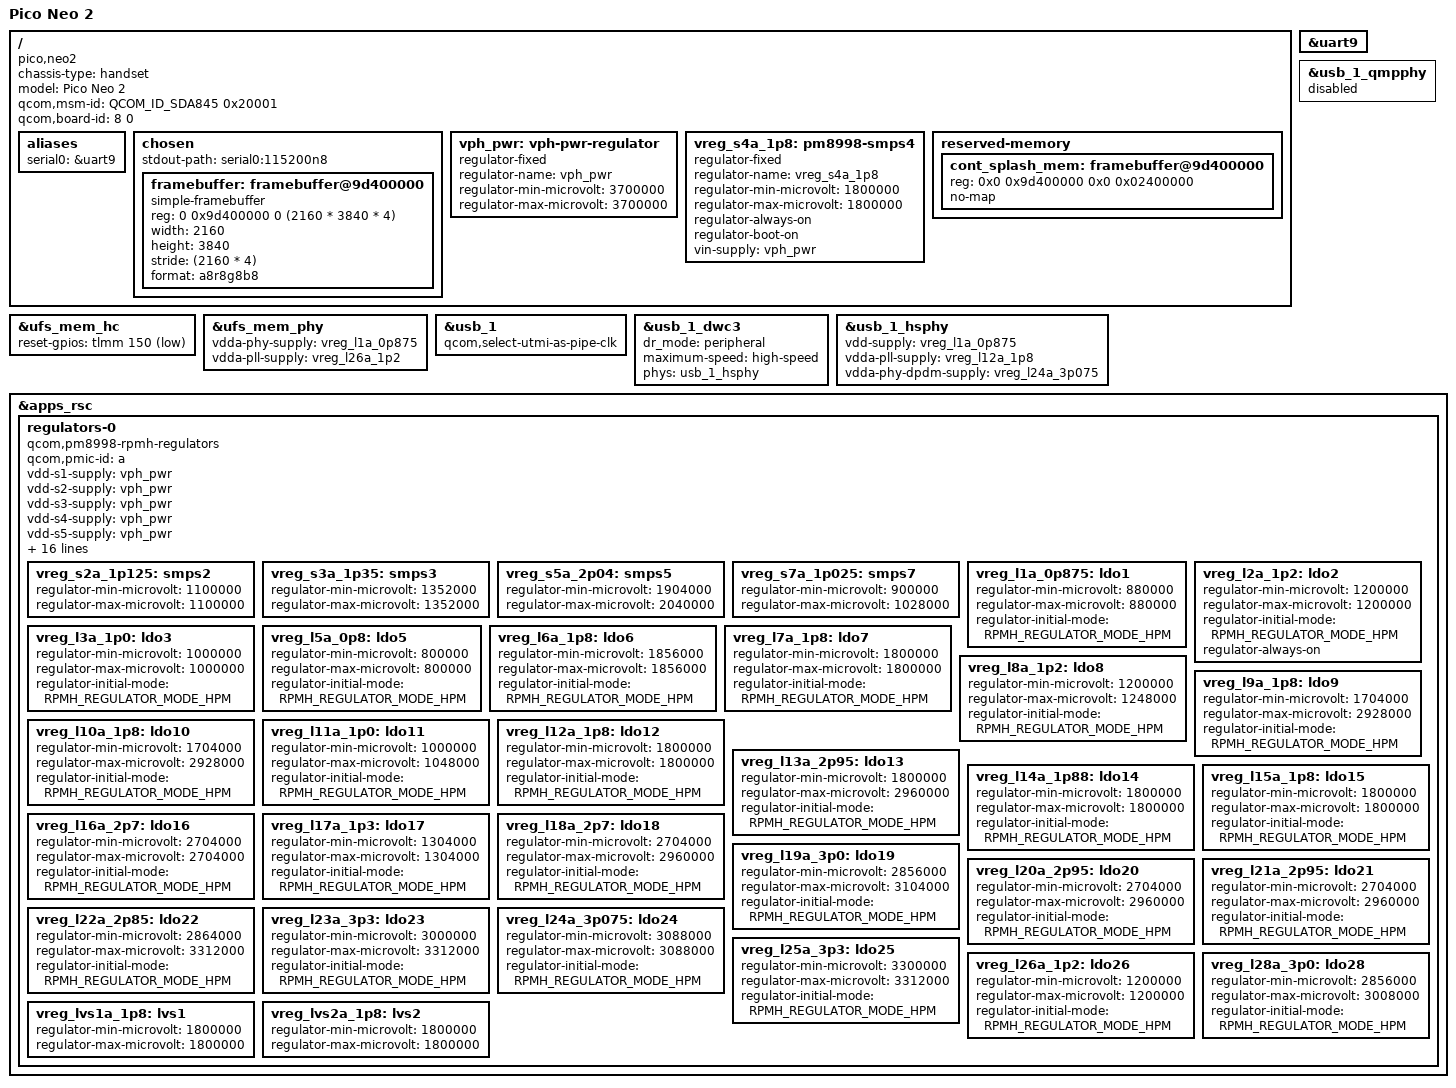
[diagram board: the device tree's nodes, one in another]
// SPDX-License-Identifier: GPL-2.0
/*
 * SDM845 Pico Neo 2 (A7B10) device tree source
 *
 * The Pico Neo 2 is a standalone VR headset based on the Qualcomm SDM845 SoC.
 * This DTS is maintained in the pico-linux repo and copied into the kernel
 * tree at build time.
 */

/dts-v1/;

#include <dt-bindings/arm/qcom,ids.h>
#include <dt-bindings/gpio/gpio.h>
#include <dt-bindings/regulator/qcom,rpmh-regulator.h>

#include "sdm845.dtsi"
#include "pm8998.dtsi"

/ {
	chassis-type = "handset";
	model = "Pico Neo 2";
	compatible = "pico,neo2", "qcom,sdm845";
	qcom,msm-id = <QCOM_ID_SDA845 0x20001>;
	qcom,board-id = <8 0>;

	aliases {
		serial0 = &uart9;
	};

	chosen {
		#address-cells = <2>;
		#size-cells = <2>;
		ranges;

		stdout-path = "serial0:115200n8";

		framebuffer: framebuffer@9d400000 {
			compatible = "simple-framebuffer";
			reg = <0 0x9d400000 0 (2160 * 3840 * 4)>;
			width = <2160>;
			height = <3840>;
			stride = <(2160 * 4)>;
			format = "a8r8g8b8";
		};
	};

	vph_pwr: vph-pwr-regulator {
		compatible = "regulator-fixed";
		regulator-name = "vph_pwr";
		regulator-min-microvolt = <3700000>;
		regulator-max-microvolt = <3700000>;
	};

	vreg_s4a_1p8: pm8998-smps4 {
		compatible = "regulator-fixed";
		regulator-name = "vreg_s4a_1p8";
		regulator-min-microvolt = <1800000>;
		regulator-max-microvolt = <1800000>;
		regulator-always-on;
		regulator-boot-on;
		vin-supply = <&vph_pwr>;
	};

	reserved-memory {
		cont_splash_mem: framebuffer@9d400000 {
			reg = <0x0 0x9d400000 0x0 0x02400000>;
			no-map;
		};
	};
};

&uart9 {
	status = "okay";
};

&ufs_mem_hc {
	reset-gpios = <&tlmm 150 GPIO_ACTIVE_LOW>;
	status = "okay";
};

&ufs_mem_phy {
	vdda-phy-supply = <&vreg_l1a_0p875>;
	vdda-pll-supply = <&vreg_l26a_1p2>;
	status = "okay";
};

&usb_1 {
	status = "okay";
	qcom,select-utmi-as-pipe-clk;
};

&usb_1_dwc3 {
	dr_mode = "peripheral";
	maximum-speed = "high-speed";
	/delete-property/ phys;
	/delete-property/ phy-names;
	phys = <&usb_1_hsphy>;
	phy-names = "usb2-phy";
};

&usb_1_hsphy {
	status = "okay";
	vdd-supply = <&vreg_l1a_0p875>;
	vdda-pll-supply = <&vreg_l12a_1p8>;
	vdda-phy-dpdm-supply = <&vreg_l24a_3p075>;
};

&usb_1_qmpphy {
	status = "disabled";
};

&apps_rsc {
	regulators-0 {
		compatible = "qcom,pm8998-rpmh-regulators";
		qcom,pmic-id = "a";

		vdd-s1-supply = <&vph_pwr>;
		vdd-s2-supply = <&vph_pwr>;
		vdd-s3-supply = <&vph_pwr>;
		vdd-s4-supply = <&vph_pwr>;
		vdd-s5-supply = <&vph_pwr>;
		vdd-s6-supply = <&vph_pwr>;
		vdd-s7-supply = <&vph_pwr>;
		vdd-s8-supply = <&vph_pwr>;
		vdd-s9-supply = <&vph_pwr>;
		vdd-s10-supply = <&vph_pwr>;
		vdd-s11-supply = <&vph_pwr>;
		vdd-s12-supply = <&vph_pwr>;
		vdd-s13-supply = <&vph_pwr>;
		vdd-l1-l27-supply = <&vreg_s7a_1p025>;
		vdd-l2-l8-l17-supply = <&vreg_s3a_1p35>;
		vdd-l3-l11-supply = <&vreg_s7a_1p025>;
		vdd-l4-l5-supply = <&vreg_s7a_1p025>;
		vdd-l6-supply = <&vph_pwr>;
		vdd-l7-l12-l14-l15-supply = <&vreg_s5a_2p04>;
		vdd-l26-supply = <&vreg_s3a_1p35>;
		vin-lvs-1-2-supply = <&vreg_s4a_1p8>;

		vreg_s2a_1p125: smps2 {
			regulator-min-microvolt = <1100000>;
			regulator-max-microvolt = <1100000>;
		};

		vreg_s3a_1p35: smps3 {
			regulator-min-microvolt = <1352000>;
			regulator-max-microvolt = <1352000>;
		};

		vreg_s5a_2p04: smps5 {
			regulator-min-microvolt = <1904000>;
			regulator-max-microvolt = <2040000>;
		};

		vreg_s7a_1p025: smps7 {
			regulator-min-microvolt = <900000>;
			regulator-max-microvolt = <1028000>;
		};

		vreg_l1a_0p875: ldo1 {
			regulator-min-microvolt = <880000>;
			regulator-max-microvolt = <880000>;
			regulator-initial-mode = <RPMH_REGULATOR_MODE_HPM>;
		};

		vreg_l2a_1p2: ldo2 {
			regulator-min-microvolt = <1200000>;
			regulator-max-microvolt = <1200000>;
			regulator-initial-mode = <RPMH_REGULATOR_MODE_HPM>;
			regulator-always-on;
		};

		vreg_l3a_1p0: ldo3 {
			regulator-min-microvolt = <1000000>;
			regulator-max-microvolt = <1000000>;
			regulator-initial-mode = <RPMH_REGULATOR_MODE_HPM>;
		};

		vreg_l5a_0p8: ldo5 {
			regulator-min-microvolt = <800000>;
			regulator-max-microvolt = <800000>;
			regulator-initial-mode = <RPMH_REGULATOR_MODE_HPM>;
		};

		vreg_l6a_1p8: ldo6 {
			regulator-min-microvolt = <1856000>;
			regulator-max-microvolt = <1856000>;
			regulator-initial-mode = <RPMH_REGULATOR_MODE_HPM>;
		};

		vreg_l7a_1p8: ldo7 {
			regulator-min-microvolt = <1800000>;
			regulator-max-microvolt = <1800000>;
			regulator-initial-mode = <RPMH_REGULATOR_MODE_HPM>;
		};

		vreg_l8a_1p2: ldo8 {
			regulator-min-microvolt = <1200000>;
			regulator-max-microvolt = <1248000>;
			regulator-initial-mode = <RPMH_REGULATOR_MODE_HPM>;
		};

		vreg_l9a_1p8: ldo9 {
			regulator-min-microvolt = <1704000>;
			regulator-max-microvolt = <2928000>;
			regulator-initial-mode = <RPMH_REGULATOR_MODE_HPM>;
		};

		vreg_l10a_1p8: ldo10 {
			regulator-min-microvolt = <1704000>;
			regulator-max-microvolt = <2928000>;
			regulator-initial-mode = <RPMH_REGULATOR_MODE_HPM>;
		};

		vreg_l11a_1p0: ldo11 {
			regulator-min-microvolt = <1000000>;
			regulator-max-microvolt = <1048000>;
			regulator-initial-mode = <RPMH_REGULATOR_MODE_HPM>;
		};

		vreg_l12a_1p8: ldo12 {
			regulator-min-microvolt = <1800000>;
			regulator-max-microvolt = <1800000>;
			regulator-initial-mode = <RPMH_REGULATOR_MODE_HPM>;
		};

		vreg_l13a_2p95: ldo13 {
			regulator-min-microvolt = <1800000>;
			regulator-max-microvolt = <2960000>;
			regulator-initial-mode = <RPMH_REGULATOR_MODE_HPM>;
		};

		vreg_l14a_1p88: ldo14 {
			regulator-min-microvolt = <1800000>;
			regulator-max-microvolt = <1800000>;
			regulator-initial-mode = <RPMH_REGULATOR_MODE_HPM>;
		};

		vreg_l15a_1p8: ldo15 {
			regulator-min-microvolt = <1800000>;
			regulator-max-microvolt = <1800000>;
			regulator-initial-mode = <RPMH_REGULATOR_MODE_HPM>;
		};

		vreg_l16a_2p7: ldo16 {
			regulator-min-microvolt = <2704000>;
			regulator-max-microvolt = <2704000>;
			regulator-initial-mode = <RPMH_REGULATOR_MODE_HPM>;
		};

		vreg_l17a_1p3: ldo17 {
			regulator-min-microvolt = <1304000>;
			regulator-max-microvolt = <1304000>;
			regulator-initial-mode = <RPMH_REGULATOR_MODE_HPM>;
		};

		vreg_l18a_2p7: ldo18 {
			regulator-min-microvolt = <2704000>;
			regulator-max-microvolt = <2960000>;
			regulator-initial-mode = <RPMH_REGULATOR_MODE_HPM>;
		};

		vreg_l19a_3p0: ldo19 {
			regulator-min-microvolt = <2856000>;
			regulator-max-microvolt = <3104000>;
			regulator-initial-mode = <RPMH_REGULATOR_MODE_HPM>;
		};

		vreg_l20a_2p95: ldo20 {
			regulator-min-microvolt = <2704000>;
			regulator-max-microvolt = <2960000>;
			regulator-initial-mode = <RPMH_REGULATOR_MODE_HPM>;
		};

		vreg_l21a_2p95: ldo21 {
			regulator-min-microvolt = <2704000>;
			regulator-max-microvolt = <2960000>;
			regulator-initial-mode = <RPMH_REGULATOR_MODE_HPM>;
		};

		vreg_l22a_2p85: ldo22 {
			regulator-min-microvolt = <2864000>;
			regulator-max-microvolt = <3312000>;
			regulator-initial-mode = <RPMH_REGULATOR_MODE_HPM>;
		};

		vreg_l23a_3p3: ldo23 {
			regulator-min-microvolt = <3000000>;
			regulator-max-microvolt = <3312000>;
			regulator-initial-mode = <RPMH_REGULATOR_MODE_HPM>;
		};

		vreg_l24a_3p075: ldo24 {
			regulator-min-microvolt = <3088000>;
			regulator-max-microvolt = <3088000>;
			regulator-initial-mode = <RPMH_REGULATOR_MODE_HPM>;
		};

		vreg_l25a_3p3: ldo25 {
			regulator-min-microvolt = <3300000>;
			regulator-max-microvolt = <3312000>;
			regulator-initial-mode = <RPMH_REGULATOR_MODE_HPM>;
		};

		vreg_l26a_1p2: ldo26 {
			regulator-min-microvolt = <1200000>;
			regulator-max-microvolt = <1200000>;
			regulator-initial-mode = <RPMH_REGULATOR_MODE_HPM>;
		};

		vreg_l28a_3p0: ldo28 {
			regulator-min-microvolt = <2856000>;
			regulator-max-microvolt = <3008000>;
			regulator-initial-mode = <RPMH_REGULATOR_MODE_HPM>;
		};

		vreg_lvs1a_1p8: lvs1 {
			regulator-min-microvolt = <1800000>;
			regulator-max-microvolt = <1800000>;
		};

		vreg_lvs2a_1p8: lvs2 {
			regulator-min-microvolt = <1800000>;
			regulator-max-microvolt = <1800000>;
		};
	};
};
